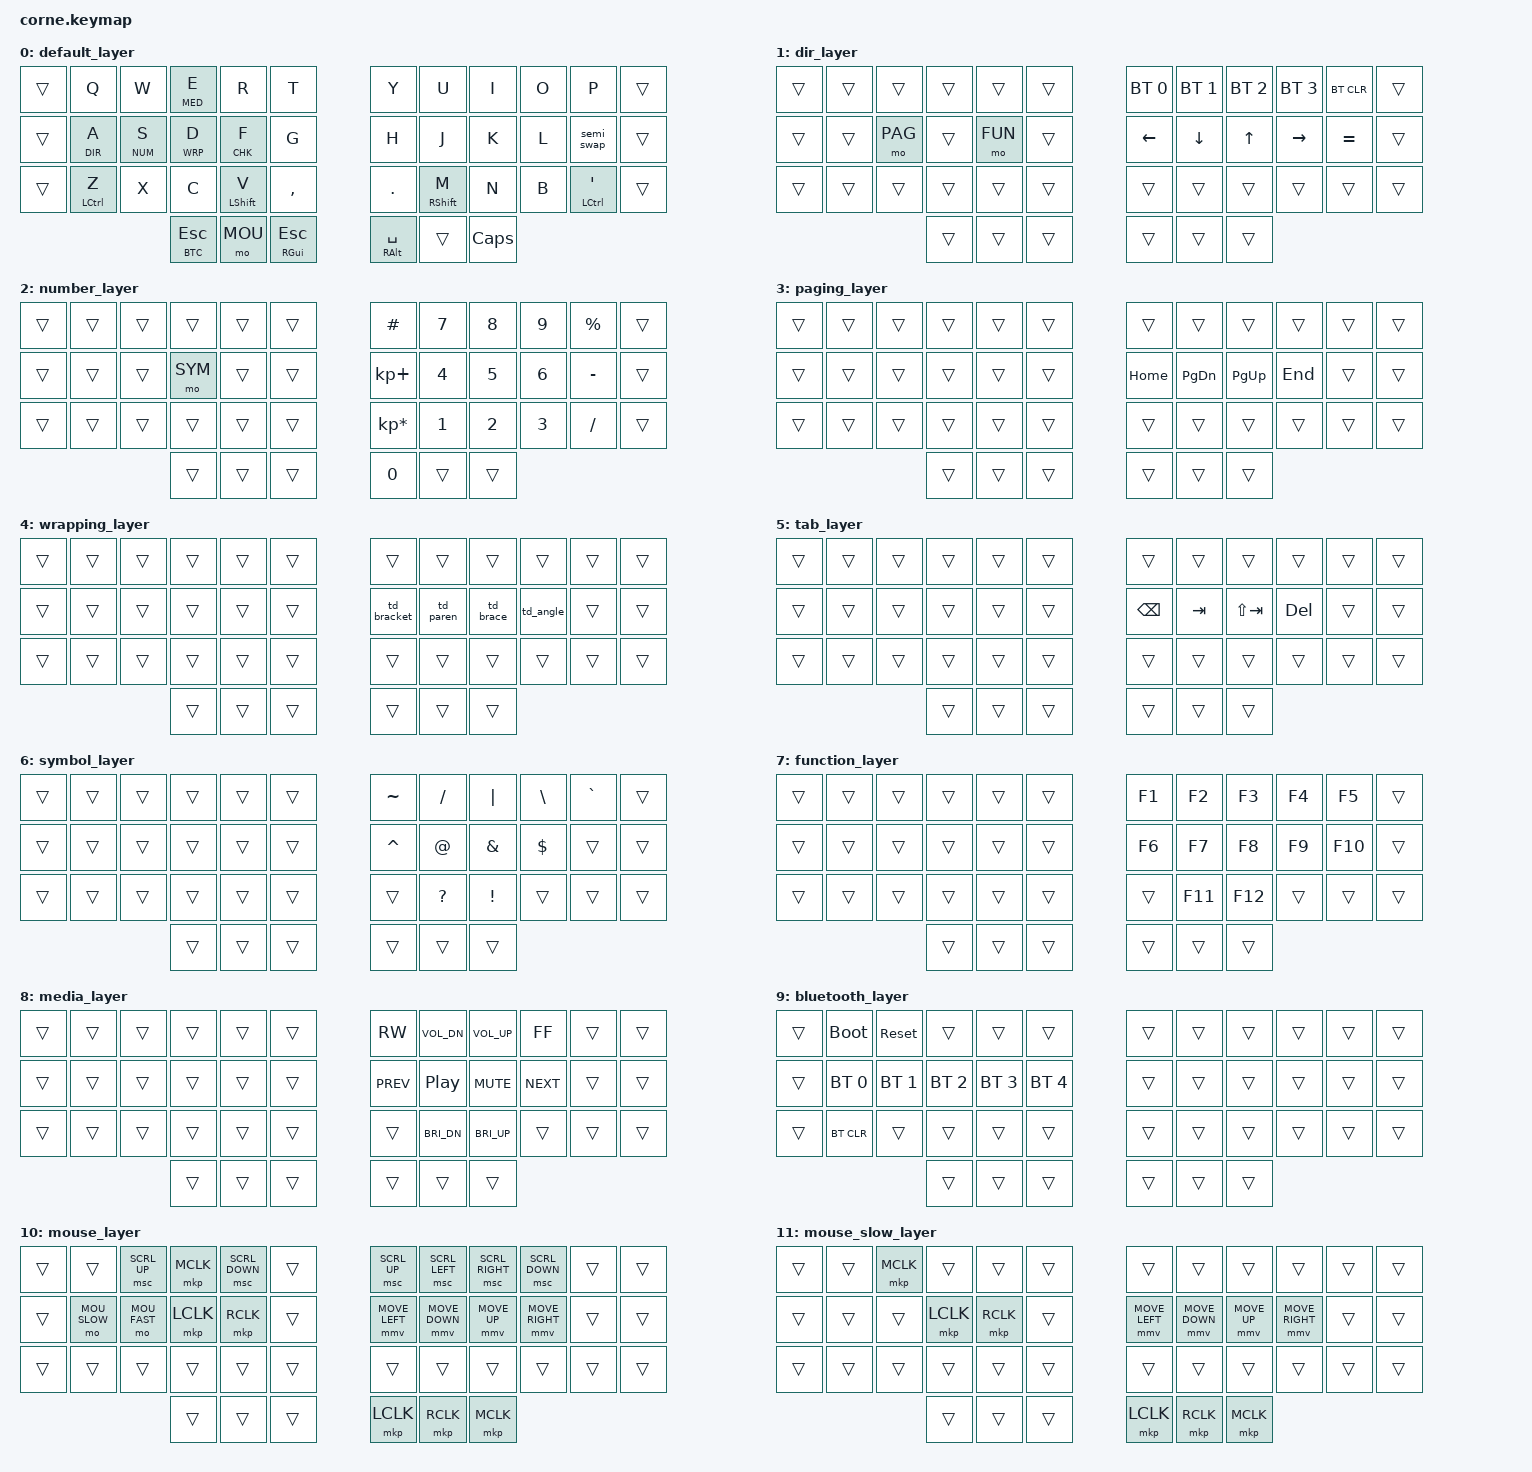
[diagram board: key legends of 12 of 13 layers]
/*
 * Copyright (c) 2020 The ZMK Contributors
 *
 * SPDX-License-Identifier: MIT
 */

#include <behaviors.dtsi>
#include <dt-bindings/zmk/keys.h>
#include <dt-bindings/zmk/bt.h>
#include <dt-bindings/zmk/reset.h>
// Mouse support requires newer ZMK version (now on main branch)
#include <dt-bindings/zmk/mouse.h>

#define DEF 0
#define DIR 1
#define NUM 2
#define PAG 3
#define WRP 4
#define CHK 5
#define SYM 6
#define FUN 7
#define MED 8
#define BTC 9
#define MOU 10
#define MOU_SLOW 11
#define MOU_FAST 12


&mt {
        tapping-term-ms = <450>;
        quick-tap-ms = <175>;
        require-prior-idle-ms = <150>;
};

/ {


        behaviors {
                // Per-finger optimized hold-tap behaviors
                // Pinky fingers (220-280ms) - slower, weaker fingers
                hm_pinky: homerow_mod_pinky {
                        compatible = "zmk,behavior-hold-tap";
                        label = "HOMEROW_MOD_PINKY";
                        #binding-cells = <2>;
                        tapping-term-ms = <280>;
                        quick-tap-ms = <175>;
                        require-prior-idle-ms = <150>;
                        flavor = "balanced";
                        bindings = <&kp>, <&kp>;
                };

                lt_pinky: layer_tap_pinky {
                        compatible = "zmk,behavior-hold-tap";
                        label = "LAYER_TAP_PINKY";
                        #binding-cells = <2>;
                        tapping-term-ms = <280>;
                        quick-tap-ms = <175>;
                        require-prior-idle-ms = <150>;
                        flavor = "balanced";
                        bindings = <&mo>, <&kp>;
                };

                // Ring fingers (220-260ms) - slightly stronger than pinky
                hm_ring: homerow_mod_ring {
                        compatible = "zmk,behavior-hold-tap";
                        label = "HOMEROW_MOD_RING";
                        #binding-cells = <2>;
                        tapping-term-ms = <250>;
                        quick-tap-ms = <175>;
                        require-prior-idle-ms = <150>;
                        flavor = "balanced";
                        bindings = <&kp>, <&kp>;
                };

                lt_ring: layer_tap_ring {
                        compatible = "zmk,behavior-hold-tap";
                        label = "LAYER_TAP_RING";
                        #binding-cells = <2>;
                        tapping-term-ms = <250>;
                        quick-tap-ms = <175>;
                        require-prior-idle-ms = <150>;
                        flavor = "balanced";
                        bindings = <&mo>, <&kp>;
                };

                // Middle fingers (210-240ms) - stronger, more coordinated
                hm_middle: homerow_mod_middle {
                        compatible = "zmk,behavior-hold-tap";
                        label = "HOMEROW_MOD_MIDDLE";
                        #binding-cells = <2>;
                        tapping-term-ms = <230>;
                        quick-tap-ms = <175>;
                        require-prior-idle-ms = <150>;
                        flavor = "balanced";
                        bindings = <&kp>, <&kp>;
                };

                lt_middle: layer_tap_middle {
                        compatible = "zmk,behavior-hold-tap";
                        label = "LAYER_TAP_MIDDLE";
                        #binding-cells = <2>;
                        tapping-term-ms = <230>;
                        quick-tap-ms = <175>;
                        require-prior-idle-ms = <150>;
                        flavor = "balanced";
                        bindings = <&mo>, <&kp>;
                };

                // Index fingers (200-220ms) - strongest, most agile
                hm_index: homerow_mod_index {
                        compatible = "zmk,behavior-hold-tap";
                        label = "HOMEROW_MOD_INDEX";
                        #binding-cells = <2>;
                        tapping-term-ms = <200>;
                        quick-tap-ms = <175>;
                        require-prior-idle-ms = <125>;
                        flavor = "balanced";
                        bindings = <&kp>, <&kp>;
                };

                lt_index: layer_tap_index {
                        compatible = "zmk,behavior-hold-tap";
                        label = "LAYER_TAP_INDEX";
                        #binding-cells = <2>;
                        tapping-term-ms = <200>;
                        quick-tap-ms = <175>;
                        require-prior-idle-ms = <125>;
                        flavor = "balanced";
                        bindings = <&mo>, <&kp>;
                };

                // Thumb keys (200-250ms) - strong but different motion
                hm_thumb: homerow_mod_thumb {
                        compatible = "zmk,behavior-hold-tap";
                        label = "HOMEROW_MOD_THUMB";
                        #binding-cells = <2>;
                        tapping-term-ms = <200>;
                        quick-tap-ms = <175>;
                        require-prior-idle-ms = <125>;
                        flavor = "balanced";
                        bindings = <&kp>, <&kp>;
                };

                lt_thumb: layer_tap_thumb {
                        compatible = "zmk,behavior-hold-tap";
                        label = "LAYER_TAP_THUMB";
                        #binding-cells = <2>;
                        tapping-term-ms = <200>;
                        quick-tap-ms = <175>;
                        require-prior-idle-ms = <125>;
                        flavor = "balanced";
                        bindings = <&mo>, <&kp>;
                };

                // Dedicated shift behaviors for fast typing
                hm_shift: homerow_shift {
                        compatible = "zmk,behavior-hold-tap";
                        label = "HOMEROW_SHIFT";
                        #binding-cells = <2>;
                        tapping-term-ms = <200>;
                        quick-tap-ms = <175>;
                        require-prior-idle-ms = <125>;
                        flavor = "balanced";
                        bindings = <&kp>, <&kp>;
                };


                semi_swap: grave_escape {
                        compatible = "zmk,behavior-mod-morph";
                        label = "SEMI_SWAP";
                        #binding-cells = <0>;
                        bindings = <&kp COLON>, <&kp SEMI>;
                        mods = <(MOD_LSFT|MOD_RSFT)>;
                };

                lm: letter_mods {
                        compatible = "zmk,behavior-hold-tap";
                        label = "LETTER_MODS";
                        #binding-cells = <2>;
                        tapping-term-ms = <300>;
                        quick-tap-ms = <175>;
                        require-prior-idle-ms = <125>;
                        flavor = "balanced";
                        bindings = <&kp>, <&kp>;
                };

                td_esc_caps: tap_dance_esc_caps {
                        compatible = "zmk,behavior-tap-dance";
                        label = "TAP_DANCE_ESC_CAPS";
                        #binding-cells = <0>;
                        tapping-term-ms = <200>;
                        bindings = <&kp ESC>, <&kp CAPS>;
                };

                td_paren: tap_dance_parenthesis {
                        compatible = "zmk,behavior-tap-dance";
                        label = "TAP_DANCE_PAREN";
                        #binding-cells = <0>;
                        tapping-term-ms = <300>;
                        bindings = <&kp LPAR>, <&kp RPAR>;
                };

                td_bracket: tap_dance_bracket {
                        compatible = "zmk,behavior-tap-dance";
                        label = "TAP_DANCE_BRACKET";
                        #binding-cells = <0>;
                        tapping-term-ms = <300>;
                        bindings = <&kp LBKT>, <&kp RBKT>;
                };

                td_brace: tap_dance_brace {
                        compatible = "zmk,behavior-tap-dance";
                        label = "TAP_DANCE_BRACE";
                        #binding-cells = <0>;
                        tapping-term-ms = <300>;
                        bindings = <&kp LBRC>, <&kp RBRC>;
                };

                td_angle: tap_dance_angle {
                        compatible = "zmk,behavior-tap-dance";
                        label = "TAP_DANCE_ANGLE";
                        #binding-cells = <0>;
                        tapping-term-ms = <300>;
                        bindings = <&kp LT>, <&kp GT>;
                };

        };

        combos {
                compatible = "zmk,combos";

                combo_esc {
                        timeout-ms = <120>;
                        key-positions = <20 21>;
                        bindings = <&td_esc_caps>;
                        require-prior-idle-ms = <100>;
                };

                combo_ret {
                        timeout-ms = <120>;
                        key-positions = <19 20>;
                        bindings = <&kp RET>;
                        require-prior-idle-ms = <100>;
                };

                combo_sav {
                        timeout-ms = <100>;
                        key-positions = <18 21>;
                        bindings = <&kp LC(S)>;
                        require-prior-idle-ms = <100>;
                };

                combo_tab {
                        timeout-ms = <120>;
                        key-positions = <1 2>;
                        bindings = <&kp TAB>;
                        require-prior-idle-ms = <100>;
                };

        };

        keymap {
                compatible = "zmk,keymap";

                default_layer {
//    --------------------------------                  -------------------------------
//    |  Q  |  W  |  E  |  R  |  T   |                  |  Y  |  U  |  I  |  O  |  P  |
//    |  A  |  S  |  D  |  F  |  G   |                  |  H  |  J  |  K  |  L  | :/; |
//    |  Z  |  X  |  C  |  V  |  ,   |-------     ------|  .  |  M  |  N  |  B  |  '  |
//    ------------------| BTC | MOU  | RGUI |     | SPC | VIM |     |------------------
//                      ---------------------     -------------------
                        bindings = <
&trans  &kp Q              &kp W           &lt MED E         &kp R                    &kp T         &kp Y         &kp U                    &kp I            &kp O           &kp P          &trans
&trans  &lt_pinky DIR A    &lt_ring NUM S  &lt_middle WRP D  &lt_index CHK F          &kp G         &kp H         &kp J                    &kp K            &kp L           &semi_swap     &trans
&trans  &hm_pinky LCTRL Z  &kp X           &kp C             &hm_shift LSHFT V  &kp COMMA     &kp DOT       &hm_shift RSHFT M  &kp N            &kp B           &hm_pinky LCTRL SQT  &trans
                                           &lt BTC ESC       &mo MOU                  &hm_thumb RGUI ESC  &hm_thumb RALT SPC  &trans           &kp CAPS
                        >;
                };

                dir_layer {
//    -------------------------------                  ------------------------------
//    |      |     |     |     |     |                 |     |    |     |     |     |
//    |      | PAG |     | FUN |     |                 | LFT | UP | DWN | RHT | EQL |
//    |      |     |     |     |     |------     ------|     |    |     |     |     |
//    -------------------|     |     |     |     |     |     |    |------------------
//                       -------------------     ------------------
                        bindings = <
&trans  &trans  &trans   &trans  &trans   &trans        &bt BT_SEL 0  &bt BT_SEL 1  &bt BT_SEL 2  &bt BT_SEL 3  &bt BT_CLR  &trans
&trans  &trans  &mo PAG  &trans  &mo FUN  &trans        &kp LEFT      &kp DOWN      &kp UP        &kp RIGHT     &kp EQUAL   &trans
&trans  &trans  &trans   &trans  &trans   &trans        &trans        &trans        &trans        &trans        &trans      &trans
                         &trans  &trans   &trans        &trans        &trans        &trans
                        >;
                };

                number_layer {
//     -------------------------------                 -------------------------------
//     |     |     |     |     |     |                 |  #  |  7  |  8  |  9  |  %  |
//     |     |     | SYM |     |     |                 |  +  |  4  |  5  |  6  |  -  |
//     |     |     |     |     |     |------     ------|  *  |  1  |  2  |  3  |  /  |
//     ------------------|     |     |     |     |  0  |  ,  |  .  |------------------
//                       -------------------     -------------------
                        bindings = <
&trans  &trans  &trans  &trans   &trans  &trans        &kp HASH         &kp N7     &kp N8  &kp N9  &kp PRCNT  &trans
&trans  &trans  &trans  &mo SYM  &trans  &trans        &kp KP_PLUS      &kp N4     &kp N5  &kp N6  &kp MINUS  &trans
&trans  &trans  &trans  &trans   &trans  &trans        &kp KP_MULTIPLY  &kp N1     &kp N2  &kp N3  &kp FSLH   &trans
                        &trans   &trans  &trans        &kp N0           &trans     &trans
                        >;
                };

                paging_layer {
//     --------------------------------                  ----------------------------------
//     |      |     |     |     |     |                  |      |      |      |     |     |
//     |      |     |     |     |     |                  | HOME | PGUP | PGDN | END |     |
//     |      |     |     |     |     |------     -------|      |      |      |     |     |
//     -------------------|     |     |     |     |      |      |      |-------------------
//                        -------------------     ---------------------
                        bindings = <
&trans  &trans  &trans  &trans  &trans  &trans        &trans    &trans     &trans     &trans   &trans  &trans
&trans  &trans  &trans  &trans  &trans  &trans        &kp HOME  &kp PG_DN  &kp PG_UP  &kp END  &trans  &trans
&trans  &trans  &trans  &trans  &trans  &trans        &trans    &trans     &trans     &trans   &trans  &trans
                        &trans  &trans  &trans        &trans    &trans     &trans
                        >;
                };

                wrapping_layer {
//     -------------------------------                   -------------------------------
//     |      |     |     |     |     |                  |     |     |     |     |     |
//     |      |     |     |     |     |                  | [/] | (/) | {/} | </> |     |
//     |      |     |     |     |     |------     -------|     |     |     |     |     |
//     -------------------|     |     |     |     |      |     |     |------------------
//                        -------------------     --------------------
                        bindings = <
&trans  &trans  &trans  &trans  &trans  &trans        &trans       &trans       &trans       &trans      &trans  &trans
&trans  &trans  &trans  &trans  &trans  &trans        &td_bracket  &td_paren    &td_brace    &td_angle   &trans  &trans
&trans  &trans  &trans  &trans  &trans  &trans        &trans       &trans       &trans       &trans      &trans  &trans
                        &trans  &trans  &trans        &trans       &trans       &trans
                        >;
                };

                tab_layer {
//     --------------------------------                  ----------------------------------
//     |      |     |     |     |     |                  |      |     |       |     |     |
//     |      |     |     |     |     |                  | BKSP | TAB | S-TAB | DEL |     |
//     |      |     |     |     |     |------     -------|      |     |       |     |     |
//     -------------------|     |     |     |     |      |      |     |--------------------
//                        -------------------     ---------------------
                        bindings = <
&trans  &trans  &trans  &trans  &trans  &trans        &trans    &trans    &trans       &trans   &trans  &trans
&trans  &trans  &trans  &trans  &trans  &trans        &kp BSPC  &kp TAB   &kp LS(TAB)  &kp DEL  &trans  &trans
&trans  &trans  &trans  &trans  &trans  &trans        &trans    &trans    &trans       &trans   &trans  &trans
                        &trans  &trans  &trans        &trans    &trans    &trans
                        >;
                };

                symbol_layer {
//     --------------------------------                 -------------------------------
//     |      |     |     |     |     |                 |  ~  |  /  |  |  |  \  |  `  |
//     |      |     |     |     |     |                 |  ^  |  @  |  &  |  $  |     |
//     |      |     |     |     |     |------     ------|     |  ?  |  !  |     |     |
//     -------------------|     |     |     |     |     |     |     |------------------
//                        -------------------     -------------------
                        bindings = <
&trans  &trans  &trans  &trans  &trans  &trans        &kp TILDE  &kp FSLH   &kp PIPE  &kp BSLH  &kp GRAVE  &trans
&trans  &trans  &trans  &trans  &trans  &trans        &kp CARET  &kp AT     &kp AMPS  &kp DLLR  &trans     &trans
&trans  &trans  &trans  &trans  &trans  &trans        &trans     &kp QMARK  &kp EXCL  &trans    &trans     &trans
                        &trans  &trans  &trans        &trans     &trans     &trans
                        >;
                };

                function_layer {
//     ------------------------------                  --------------------------------------
//     |    |     |     |     |     |                  |  F1  |  F2   |  F3   |  F4  |  F5  |
//     |    |     |     |     |     |                  |  F6  |  F7   |  F8   |  F9  |  F10 |
//     |    |     |     |     |     |------     -------|      |  F11  |  F12  |      |      |
//     -----------------|     |     |     |     |      |      |       |----------------------
//                      -------------------     -----------------------
                        bindings = <
&trans  &trans  &trans  &trans  &trans  &trans        &kp F1  &kp F2   &kp F3   &kp F4  &kp F5   &trans
&trans  &trans  &trans  &trans  &trans  &trans        &kp F6  &kp F7   &kp F8   &kp F9  &kp F10  &trans
&trans  &trans  &trans  &trans  &trans  &trans        &trans  &kp F11  &kp F12  &trans  &trans   &trans
                        &trans  &trans  &trans        &trans  &trans   &trans
                        >;
                };

                media_layer {
//     --------------------------------                  --------------------------------------
//     |      |     |     |     |     |                  |  RW  | VOL-  |  VOL+ |  FF  |      |
//     |      |     |     |     |     |                  | PREV | PLAY  |  MUTE | NEXT |      |
//     |      |     |     |     |     |------     -------|      | BRI-  |  BRI+ |      |      |
//     -------------------|     |     |     |     |      |      |       |----------------------
//                        -------------------     -----------------------
                        bindings = <
&trans  &trans  &trans  &trans  &trans  &trans        &kp C_RW    &kp C_VOL_DN  &kp C_VOL_UP  &kp C_FF    &trans  &trans
&trans  &trans  &trans  &trans  &trans  &trans        &kp C_PREV  &kp C_PP      &kp C_MUTE    &kp C_NEXT  &trans  &trans
&trans  &trans  &trans  &trans  &trans  &trans        &trans      &kp C_BRI_DN  &kp C_BRI_UP  &trans      &trans  &trans
                        &trans  &trans  &trans        &trans      &trans        &trans
                        >;
                };

                bluetooth_layer {
//     ┌─────┬─────┬─────┬─────┬─────┐                  ┌─────┬─────┬─────┬─────┬─────┐
//     │BOOT │RESET│     │     │     │                  │     │     │     │     │     │
//     ├─────┼─────┼─────┼─────┼─────┤                  ├─────┼─────┼─────┼─────┼─────┤
//     │ BT1 │ BT2 │ BT3 │ BT4 │ BT5 │                  │     │     │     │     │     │
//     ├─────┼─────┼─────┼─────┼─────┤                  ├─────┼─────┼─────┼─────┼─────┤
//     │BTCLR│     │     │     │     │                  │     │     │     │     │     │
//     └─────┴─────┴─────┼─────┼─────┼─────┐     ┌─────┼─────┼─────┼─────┴─────┴─────┘
//                       │     │     │     │     │     │     │     │
//                       └─────┴─────┴─────┘     └─────┴─────┴─────┘
                        bindings = <
&trans      &bootloader   &sys_reset    &trans        &trans        &trans        &trans      &trans  &trans  &trans  &trans  &trans
&trans      &bt BT_SEL 0  &bt BT_SEL 1  &bt BT_SEL 2  &bt BT_SEL 3  &bt BT_SEL 4  &trans      &trans  &trans  &trans  &trans  &trans
&trans      &bt BT_CLR    &trans        &trans        &trans        &trans        &trans      &trans  &trans  &trans  &trans  &trans
                                        &trans        &trans        &trans        &trans      &trans  &trans
                        >;
                };

                mouse_layer {
//     --------------------------------                  --------------------------------------
//     |      | SCUP| MID | SCDN|     |                  | SCUP | SCLT  | SCRT  | SCDN |      |
//     | SLOW | FAST|     | LFT | RHT |                  | M_L  | M_D   | M_U   | M_R  |      |
//     |      |     |     |     |     |------     -------|      |       |       |      |      |
//     -------------------|     |     |     |     | LFT  | RHT  |  MID  |----------------------
//                        -------------------     -----------------------
                        bindings = <
&trans  &trans        &msc SCRL_UP   &mkp MCLK &msc SCRL_DOWN &trans        &msc SCRL_UP     &msc SCRL_LEFT    &msc SCRL_RIGHT &msc SCRL_DOWN    &trans  &trans
&trans  &mo MOU_SLOW  &mo MOU_FAST   &mkp LCLK &mkp RCLK      &trans        &mmv MOVE_LEFT   &mmv MOVE_DOWN    &mmv MOVE_UP    &mmv MOVE_RIGHT   &trans  &trans
&trans  &trans        &trans         &trans    &trans         &trans        &trans           &trans            &trans          &trans            &trans  &trans
                                     &trans    &trans         &trans        &mkp LCLK        &mkp RCLK         &mkp MCLK
                        >;
                };

                mouse_slow_layer {
//     --------------------------------                  --------------------------------------
//     |      |     | MID |     |     |                  |      |       |       |      |      |
//     |      |     |     | LFT | RHT |                  | M_L  | M_D   | M_U   | M_R  |      |
//     |      |     |     |     |     |------     -------|      |       |       |      |      |
//     -------------------|     |     |     |     |      |      |       |----------------------
//                        -------------------     -----------------------
                        bindings = <
&trans  &trans  &mkp MCLK    &trans    &trans       &trans        &trans                &trans                 &trans               &trans                 &trans  &trans
&trans  &trans  &trans       &mkp LCLK &mkp RCLK    &trans        &mmv MOVE_LEFT        &mmv MOVE_DOWN         &mmv MOVE_UP         &mmv MOVE_RIGHT        &trans  &trans
&trans  &trans  &trans       &trans    &trans       &trans        &trans                &trans                 &trans               &trans                 &trans  &trans
                             &trans    &trans       &trans        &mkp LCLK             &mkp RCLK              &mkp MCLK
                        >;
                };

                mouse_fast_layer {
//     --------------------------------                  --------------------------------------
//     |      |     | MID |     |     |                  |      |       |       |      |      |
//     |      |     |     | LFT | RHT |                  | M_L  | M_D   | M_U   | M_R  |      |
//     |      |     |     |     |     |------     -------|      |       |       |      |      |
//     -------------------|     |     |     |     |      |      |       |----------------------
//                        -------------------     -----------------------
                        bindings = <
&trans  &trans  &mkp MCLK    &trans    &trans       &trans        &trans                &trans                 &trans               &trans                 &trans  &trans
&trans  &trans  &trans       &mkp LCLK &mkp RCLK    &trans        &mmv MOVE_LEFT        &mmv MOVE_DOWN         &mmv MOVE_UP         &mmv MOVE_RIGHT        &trans  &trans
&trans  &trans  &trans       &trans    &trans       &trans        &trans                &trans                 &trans               &trans                 &trans  &trans
                             &trans    &trans       &trans        &mkp LCLK             &mkp RCLK              &mkp MCLK
                        >;
                };


        };
};
